# TLE984x register map
Vendor: Infineon Technologies AG; File version: 1.6
CPU: CM0 r0p0, little endian, no MPU, no FPU, 2 interrupt priority bits
Registers are 32-bit, read-write, no defined reset value unless marked. A register's access mark holds for its fields unless they carry their own. Offsets are from the block's base; [hi:lo] are bit positions; {n}, {i} and the like mark numbered series; 'fields as' and 'values as' point back to an identical list.

## SCU
Base 0x50005000
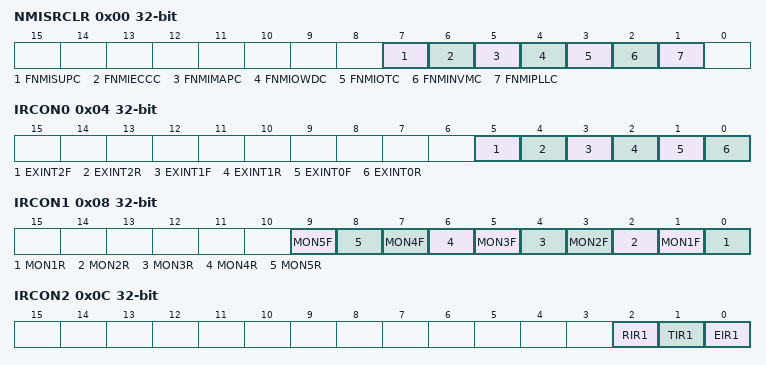
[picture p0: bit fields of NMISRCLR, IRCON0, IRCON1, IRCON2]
0x00 NMISRCLR wo — NMI Status Clear Register
  [all] fields
    0=Interrupt event is not cleared; 1=Interrupt event is cleared
  [7] FNMISUPC — Supply Prewarning NMI Flag
  [6] FNMIECCC — ECC Error NMI Flag
  [5] FNMIMAPC — NVM Map Error NMI Flag
  [4] FNMIOWDC — Oscillator Watchdog NMI Flag
  [3] FNMIOTC — Overtemperature NMI Flag
  [2] FNMINVMC — NVM Operation Complete NMI Flag
  [1] FNMIPLLC — PLL NMI Flag
0x04 IRCON0 ro — Interrupt Request Register 0
  [5] EXINT2F — Interrupt Flag for External Interrupt 2x on falling edge
    0=Interrupt on falling edge event has not occurred; 1=Interrupt on falling edge event has occurred
  [4] EXINT2R — Interrupt Flag for External Interrupt 2x on rising edge
    0=Interrupt on rising edge event has not occurred; 1=Interrupt on rising edge event has occurred
  [3] EXINT1F — Interrupt Flag for External Interrupt 1x on falling edge
    values as EXINT2F
  [2] EXINT1R — Interrupt Flag for External Interrupt 1x on rising edge
    values as EXINT2R
  [1] EXINT0F — Interrupt Flag for External Interrupt 0x on falling edge
    values as EXINT2F
  [0] EXINT0R — Interrupt Flag for External Interrupt 0x on rising edge
    values as EXINT2R
0x08 IRCON1 ro — Interrupt Request Register 1
  [2n-1] MON{n}F (n=1..5) — Interrupt Flag for MON{n}x on falling edge
    values as IRCON0.EXINT2F
  [2n-2] MON{n}R (n=1..5) — Interrupt Flag for MON{n}x on rising edge
    values as IRCON0.EXINT2R
0x0C IRCON2 ro — Interrupt Request Register 2
  [all] fields
    0=Interrupt event has not occurred; 1=Interrupt event has occurred
  [2] RIR1 — Receive Interrupt Flag for SSC1
  [1] TIR1 — Transmit Interrupt Flag for SSC1
  [0] EIR1 — Error Interrupt Flag for SSC1
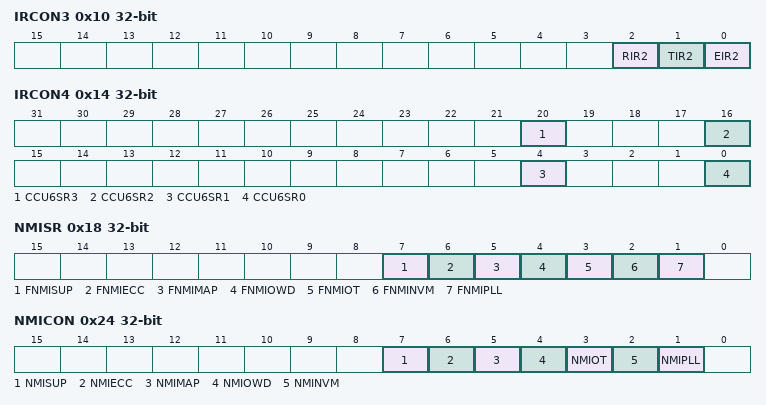
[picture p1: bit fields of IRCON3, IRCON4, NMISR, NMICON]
0x10 IRCON3 ro — Interrupt Request Register 3
  [all] fields
    values as the fields of IRCON2
  [2] RIR2 — Receive Interrupt Flag for SSC2
  [1] TIR2 — Transmit Interrupt Flag for SSC2
  [0] EIR2 — Error Interrupt Flag for SSC2
0x14 IRCON4 ro — Interrupt Request Register 4
  [all] fields
    values as the fields of IRCON2
  [20] CCU6SR3 — Interrupt Flag 3 for CCU6
  [16] CCU6SR2 — Interrupt Flag 2 for CCU6
  [4] CCU6SR1 — Interrupt Flag 1 for CCU6
  [0] CCU6SR0 — Interrupt Flag 0 for CCU6
0x18 NMISR ro — NMI Status Register
  [7] FNMISUP — Supply Prewarning NMI Flag
    0=No supply prewarning NMI has occurred; 1=Supply prewarning has occurred
  [6] FNMIECC — ECC Error NMI Flag
    0=No uncorrectable ECC error has occurred on NVM, XRAM; 1=Uncorrectable ECC error has occurred on NVM, RAM
  [5] FNMIMAP — NVM Map Error NMI Flag
    0=No NVM Map Error NMI has occurred; 1=NVM Map Error has occurred
  [4] FNMIOWD — Oscillator Watchdog NMI Flag
    0=No oscillator watchdog NMI has occurred; 1=Oscillator watchdog event has occurred
  [3] FNMIOT — Overtemperature NMI Flag
    0=No OT NMI has occurred; 1=OT NMI event has occurred
  [2] FNMINVM — NVM Operation Complete NMI Flag
    0=No NVM NMI has occurred; 1=NVM operation complete event has occurred
  [1] FNMIPLL — PLL NMI Flag
    0=No PLL NMI has occurred; 1=PLL loss-of-lock to the external crystal has occurred
0x1C IEN0 — Interrupt Enable Register 0
  [31] EA — Global Interrupt Mask
    0=All pending interrupt requests (except NMI) are blocked from the core; 1=Pending interrupt requests are not blocked from the core
0x20 VTOR — Vector Table Reallocation Register
  [1:0] VTOR_BYP — Vector Table Bypass Mode
    0=VTOR is not remapped (ROM) (Start Address: 0x0000000000); 1=VTOR is remapped to RAM (Start Address: 0x1800000000); 2=VTOR is remapped to NVM (Start Address: 0x1100000000, begin of Customer BSL Region); 3=VTOR is remapped to NVM (Start Address: Begin of NVM Linear region after customer BSL region)
0x24 NMICON — NMI Control Register
  [7] NMISUP — Supply Prewarning NMI Enable
    0=Supply NMI is disabled; 1=Supply NMI is enabled
  [6] NMIECC — ECC Error NMI Enable
    0=ECC Error NMI is disabled; 1=ECC Error NMI is enabled
  [5] NMIMAP — NVM Map Error NMI Enable
    0=NVM Map Error NMI is disabled; 1=NVM Map Error NMI is enabled
  [4] NMIOWD — Oscillator Watchdog NMI Enable
    0=Oscillator watchdog NMI is disabled; 1=Oscillator watchdog NMI is enabled
  [3] NMIOT — NMI OT Enable
    0=NMI OT is disabled; 1=NMI OT is enabled
  [2] NMINVM — NVM Operation Complete NMI Enable
    0=NVM operation complete NMI is disabled; 1=NVM operation complete NMI is enabled
  [1] NMIPLL — PLL Loss of Lock NMI Enable
    0=PLL Loss of Lock NMI is disabled; 1=PLL Loss of Lock NMI is enabled
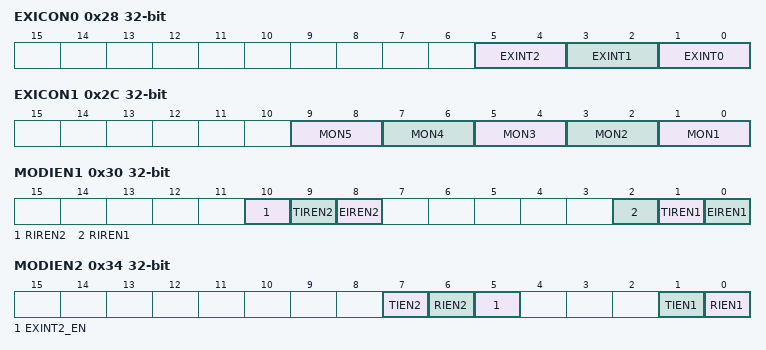
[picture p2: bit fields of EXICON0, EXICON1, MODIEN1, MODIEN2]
0x28 EXICON0 — External Interrupt Control Register 0
  [all] fields
    0=Interrupt disabled; 1=Interrupt on rising edge; 2=Interrupt on falling edge; 3=Interrupt on both rising and falling edge
  [5:4] EXINT2 — External Interrupt 2 Trigger Select
  [3:2] EXINT1 — External Interrupt 1 Trigger Select
  [1:0] EXINT0 — External Interrupt 0 Trigger Select
0x2C EXICON1 — External Interrupt Control Register 1
  [all] fields
    0=external interrupt MON is disabled; 1=Interrupt on rising edge; 2=Interrupt on falling edge; 3=Interrupt on both rising and falling edge
  [2n-1:2n-2] MON{n} (n=1..5) — MON{n} Input Trigger Select
0x30 MODIEN1 — Peripheral Interrupt Enable Register 1
  [10] RIREN2 — SSC 2 Receive Interrupt Enable
    0=Receive interrupt is disabled; 1=Receive interrupt is enabled
  [9] TIREN2 — SSC 2 Transmit Interrupt Enable
    0=Transmit interrupt is disabled; 1=Transmit interrupt is enabled
  [8] EIREN2 — SSC 2 Error Interrupt Enable
    0=Error interrupt is disabled; 1=Error interrupt is enabled
  [2] RIREN1 — SSC 1 Receive Interrupt Enable
    values as RIREN2
  [1] TIREN1 — SSC 1 Transmit Interrupt Enable
    values as TIREN2
  [0] EIREN1 — SSC 1 Error Interrupt Enable
    0=Error interrupt is disabled; 1=Error interrupt is enabled
0x34 MODIEN2 — Peripheral Interrupt Enable Register 2
  [7] TIEN2 — UART 2 Transmit Interrupt Enable
    values as MODIEN1.TIREN2
  [6] RIEN2 — UART 2 Receive Interrupt Enable
    values as MODIEN1.RIREN2
  [5] EXINT2_EN — External Interrupt 2 Enable
    0=External interrupt is disabled; 1=External interrupt is enabled
  [1] TIEN1 — UART 1 Transmit Interrupt Enable
    values as MODIEN1.TIREN2
  [0] RIEN1 — UART 1 Receive Interrupt Enable
    values as MODIEN1.RIREN2
0x38 MODIEN3 — Peripheral Interrupt Enable Register 3
  [0] IE0 — External Interrupt Enable
    0=disabled; 1=enabled
0x3C MODIEN4 — Peripheral Interrupt Enable Register 4
  [0] IE1 — External Interrupt Enable
    0=disabled; 1=enabled
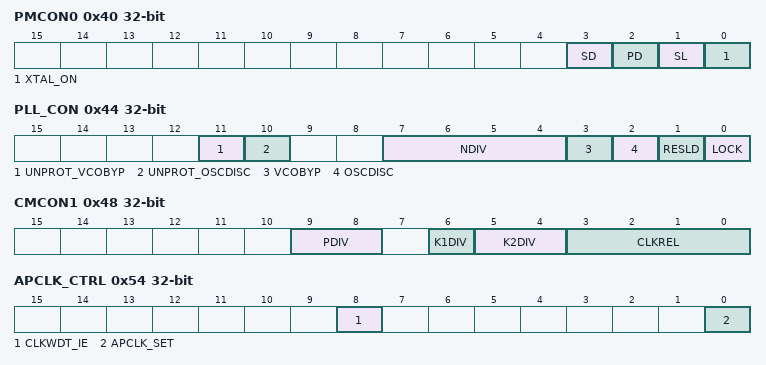
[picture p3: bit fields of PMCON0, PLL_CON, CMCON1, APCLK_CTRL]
0x40 PMCON0 — Power Mode Control Register 0
  [3] SD — Slow Down Mode Enable. Active High.
  [2] PD — Power Down Mode (Stop mode) Enable. Active High.
  [1] SL — Sleep Mode Enable. Active High.
  [0] XTAL_ON — OSC_HP Operation in Power Down Mode
    0=OSC_HP (XTAL) will be put to Power Down mode by hardware in power save mode; 1=OSC_HP (XTAL) continues to operate in Power Down mode, if enabled by SCU_OSC_CON.XPD
0x44 PLL_CON access per field — PLL Control Register
  [11] UNPROT_VCOBYP wo — Unprotect write access of VCO_BYP
  [10] UNPROT_OSCDISC wo — Unprotect write access of OSC_DISC
  [7:4] NDIV rw — PLL N-Divider
    0=N = 48; 1=N = 50; 2=N = 51; 3=N = 52; 4=N = 54; 5=N = 60; 6=N = 67; 7=N = 72; 8=N = 75; 9=N = 78; 10=N = 80; 11=N = 88; 12=N = 90; 13=N = 94; 14=N = 100; 15=N = 160
  [3] VCOBYP rw — PLL VCO Bypass Mode Select
    0=Normal (or freerunning) operation (default); 1=Prescaler Mode; VCO is bypassed (PLL output clock is derived from input clock divided by K1-divider)
  [2] OSCDISC rw — Oscillator Disconnect
    0=Oscillator is connected to the PLL; 1=Oscillator is disconnected to the PLL
  [1] RESLD rw — Restart Lock Detection
    0=No effect; 1=Reset lock flag and restart lock detection
  [0] LOCK ro — PLL Lock Status Flag
    0=The frequency difference of fREF and fDIV is greater than allowed. The VCO part of the PLL can not lock on a target frequency.; 1=The frequency difference of fREF and fDIV is small enough to enable a stable VCO operation
0x48 CMCON1 — Clock Control Register 1
  [9:8] PDIV — PLL PDIV-Divider
  [6] K1DIV — PLL K1-Divider
    0=K1 = 2; 1=K1 = 1
  [5:4] K2DIV — PLL K2-Divider
    {v}=K2 = {v+2} (v=0..3)
  [3:0] CLKREL — Slow Down Clock Divider for fCCLK Generation
    0=fsys; 1=fsys/2; 2=fsys/3; 3=fsys/4; 4=fsys/8; 5=fsys/16; 6=fsys/24; 7=fsys/32; 8=fsys/48; 9=fsys/64; 10=fsys/96; 11=fsys/128; 12=fsys/192; 13=fsys/256; 14=fsys/384; 15=fsys/512
0x4C CMCON2 — Clock Control Register 2
  [0] PBA0CLKREL — PBA0 Clock Divider
    0=divide by 1; 1=divide by 2
0x54 APCLK_CTRL — Analog Peripheral Clock Control Register
  [8] CLKWDT_IE — Clock Watchdog Interrupt Enable
    0=Interrupt disabled; 1=Interrupt enabled
  [0] APCLK_SET — Set and Overtake Flag for Clock Settings
    0=Clock Settings are ignored (previous values are held); 1=Clock Settings are overtaken
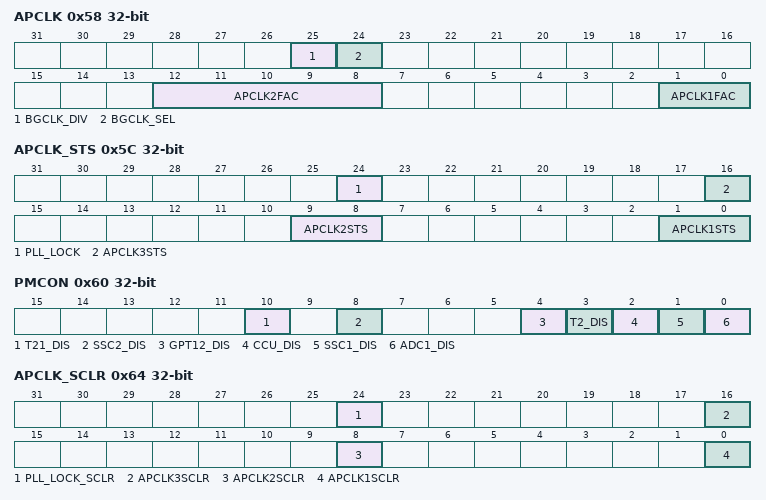
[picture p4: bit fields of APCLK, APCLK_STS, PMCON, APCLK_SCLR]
0x58 APCLK — Analog Peripheral Clock Register
  [25] BGCLK_DIV — Bandgap Clock Divider
    0=divide by 2; 1=divide by 1
  [24] BGCLK_SEL — Bandgap Clock Selection
    0=LP_CLK is selected; 1=fsys is selected
  [12:8] APCLK2FAC — Slow Down Clock Divider for TFILT_CLK Generation
    0=fsys; {v}=fsys/{v+1} (v=1..11); 30=fsys/24; 31=fsys/32
  [1:0] APCLK1FAC — Analog Module Clock Factor
    {v}=Divide by {v+1} (v=0..3)
0x5C APCLK_STS ro — Analog Peripheral Clock Status Register
  [24] PLL_LOCK — PLL LOCK Status
    0=PLL has not locked; 1=PLL has locked
  [16] APCLK3STS — Loss of Clock Status
    0=No loss of clock; 1=Loss of Lock occurred
  [9:8] APCLK2STS — Analog Peripherals Clock Status
    0=The TFILT_CLK clock is in the required range; 1=The TFILT_CLK clock exceeds the higher limit; 2=The TFILT_CLK clock exceeds the lower limit; 3=The TFILT_CLK clock is not inside the specified limit
  [1:0] APCLK1STS — Analog Peripherals Clock Status
    0=The MI_CLK clock is in the required range; 1=The MI_CLK clock exceeds the higher limit; 2=The MI_CLK clock exceeds the lower limit; 3=The MI_CLK clock is not inside the specified limit
0x60 PMCON — Peripheral Management Control Register
  [10] T21_DIS — T21 Disable Request. Active high.
    0=T21 is in normal operation. (default); 1=Request to disable the T21
  [8] SSC2_DIS — SSC2 Disable Request. Active high.
    0=SSC is in normal operation. (default); 1=Request to disable the SSC
  [4] GPT12_DIS — General Purpose Timer 12 Disable Request. Active high.
    0=GPT12 is in normal operation. (default); 1=Request to disable the GPT12
  [3] T2_DIS — T2 Disable Request. Active high.
    0=T2 is in normal operation. (default); 1=Request to disable the T2
  [2] CCU_DIS — CCU Disable Request. Active high.
    0=CCU is in normal operation. (default); 1=Request to disable the CCU
  [1] SSC1_DIS — SSC1 Disable Request. Active high.
    values as SSC2_DIS
  [0] ADC1_DIS — ADC1 Disable Request. Active high.
    0=ADC1 is in normal operation. (default); 1=Request to disable the ADC
0x64 APCLK_SCLR wo — Analog Peripheral Clock Status Clear Register
  [24] PLL_LOCK_SCLR — PLL Lock Status Clear
  [16] APCLK3SCLR — Analog Peripherals Clock 3 Status Clear
  [8] APCLK2SCLR — Analog Peripherals Clock Status Clear
  [0] APCLK1SCLR — Analog Peripherals Clock Status Clear
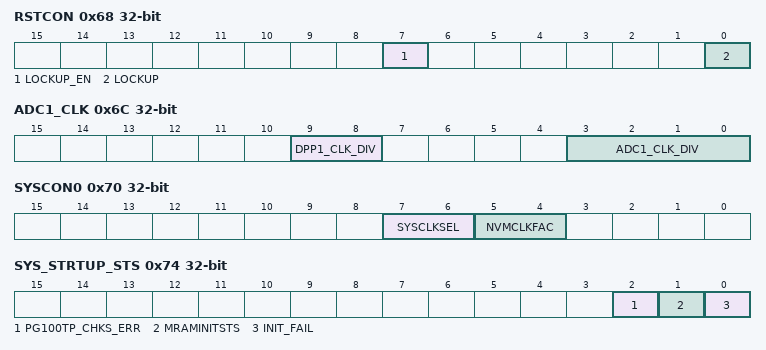
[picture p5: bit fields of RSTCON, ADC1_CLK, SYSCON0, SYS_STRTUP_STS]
0x68 RSTCON — Reset Control Register
  [7] LOCKUP_EN — Lockup Reset Enable Flag
    0=Lockup is disabled; 1=Lockup is enabled
  [0] LOCKUP — Lockup Flag
    0=Lockup Status not active; 1=Lockup Status active
0x6C ADC1_CLK — ADC1 Peripheral Clock Register
  [9:8] DPP1_CLK_DIV — ADC1 Post processing clock divider
    {v}=Divide by {v+1} (v=0..3)
  [3:0] ADC1_CLK_DIV — ADC1 Clock divider
    {v}=Divide by {v+1} (v=0..4); 15=Divide by 16
0x70 SYSCON0 access per field — System Control Register 0
  [7:6] SYSCLKSEL rw — System Clock Select
    0=The PLL clock output signal fPLL is used; 1=The direct clock input from fOSC is used; 2=The direct low-precision clock input from fLP_CLK is used; 3=The direct input from internal oscillator fINTOSC is used
  [5:4] NVMCLKFAC ro — NVM Access Clock Factor
    {v}=Divide by {v+1} (v=0..3)
0x74 SYS_STRTUP_STS ro — System Startup Status Register
  [2] PG100TP_CHKS_ERR — 100 TP Page Checksum Error
  [1] MRAMINITSTS — Map RAM Initialisation Status
  [0] INIT_FAIL — Initialization at startup failed
0x78 WAKECON — Wakeup Interrupt Control Register
  [0] WAKEUPEN — Wakeup Interrupt Enable
    0=wakeup interrupt is disabled; 1=wakeup interrupt is enabled
0x7C IRCON5 ro — Interrupt Request Register 5
  [0] WAKEUP — Interrupt Flag for Wakeup
    values as the fields of IRCON2
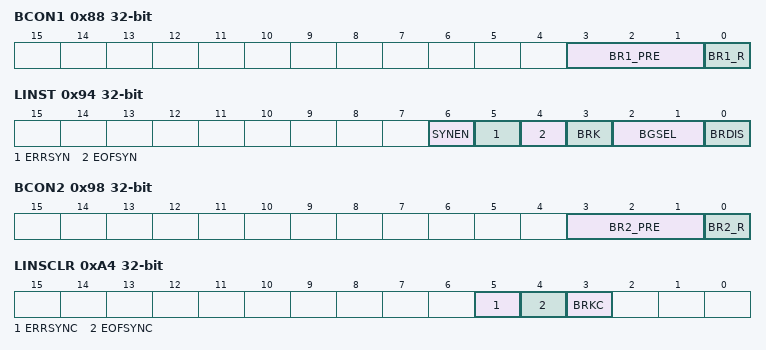
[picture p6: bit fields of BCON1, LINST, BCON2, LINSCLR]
0x88 BCON1 — Baud Rate Control Register 1
  [3:1] BR1_PRE — Prescaler Bit
    0=fDIV = fPCLK; 1=fDIV = fPCLK/2; 2=fDIV = fPCLK/4; 3=fDIV = fPCLK/8; 4=fDIV = fPCLK/16; 5=fDIV = fPCLK/32
  [0] BR1_R — Baud Rate Generator Run Control Bit
    0=Baud-rate generator disabled; 1=Baud-rate generator enabled
0x8C BGL1 — Baud Rate Timer/Reload Register, Low Byte 1
  [4:0] BG1_FD_SEL — Fractional Divider Selection
0x90 BG1 — Baud Rate Timer/Reload Register
  [10:0] BG1_BR_VALUE — Baud Rate Timer/Reload Value UART1
    0=Baud-rate timer is bypassed; 1=1; 2=2; 0x7FE=2046; 0x7FF=2047
0x94 LINST access per field — LIN Status Register
  [6] SYNEN rw — End of SYN Byte and SYN Byte Error Interrupts Enable
    0=End of SYN Byte and SYN Byte Error Interrupts are not enabled; 1=End of SYN Byte and SYN Byte Error Interrupts are enabled
  [5] ERRSYN ro — SYN Byte Error Interrupt Flag
    0=Error is not detected in SYN Byte; 1=Error is detected in SYN Byte
  [4] EOFSYN ro — End of SYN Byte Interrupt Flag
    0=End of SYN Byte is not detected; 1=End of SYN Byte is detected
  [3] BRK ro — Break Field Flag
    0=Break Field is not detected; 1=Break Field is detected
  [2:1] BGSEL rw — Baud Rate Select for Detection
  [0] BRDIS rw — Baud Rate Detection Disable
    0=Break/Synch detection is enabled; 1=Break/Synch detection is disabled
0x98 BCON2 — Baud Rate Control Register 2
  [3:1] BR2_PRE — Prescaler Bit
    values as BCON1.BR1_PRE
  [0] BR2_R — Baud Rate Generator Run Control Bit
    values as BCON1.BR1_R
0x9C BGL2 — Baud Rate Timer/Reload Register, Low Byte 2
  [4:0] BG2_FD_SEL — Fractional Divider Selection
0xA0 BG2 — Baud Rate Timer/Reload Register
  [10:0] BG2_BR_VALUE — Baud Rate Timer/Reload Value UART2
    values as BG1.BG1_BR_VALUE
0xA4 LINSCLR wo — LIN Status Clear Register
  [5] ERRSYNC — SYN Byte Error Interrupt Flag
    0=Error in SYN Byte not cleared; 1=Error in SYN Byte cleared
  [4] EOFSYNC — End of SYN Byte Interrupt Flag Clear
    0=End of SYN Byte is not cleared; 1=End of SYN Byte is cleared
  [3] BRKC — Break Field Flag Clear
    0=Break Field is not cleared; 1=Break Field is cleared
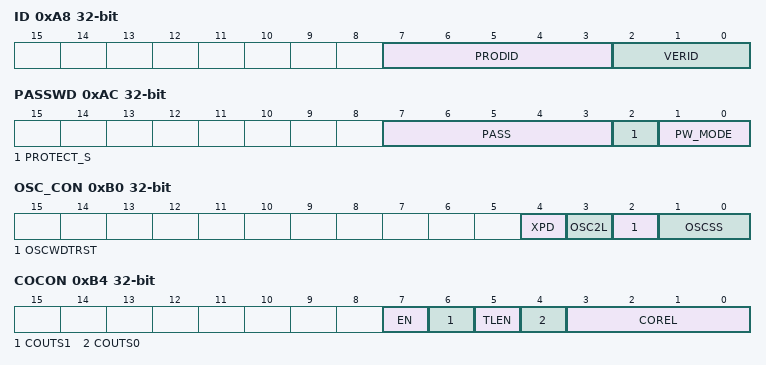
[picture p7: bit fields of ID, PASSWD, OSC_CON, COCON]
0xA8 ID ro — Identity Register
  [7:3] PRODID — Product ID
  [2:0] VERID — Version ID
0xAC PASSWD access per field — Password Register
  [7:3] PASS rw — Password Bits
    24=Enables writing of the bit field MODE; 19=Opens access to writing of all protected bits; 21=Closes access to writing of all protected bits
  [2] PROTECT_S ro — Bit-Protection Signal Status Bit
    0=Software is able to write to all protected bits; 1=Software is unable to write to any protected bits
  [1:0] PW_MODE rw — Bit-Protection Scheme Control Bit
    0=Scheme Disabled; 3=Scheme Enabled (default)
0xB0 OSC_CON access per field — OSC Control Register
  [4] XPD rw — XTAL (OSC_HP) Power Down Control
    0=XTAL (OSC_HP) is not powered down; 1=XTAL (OSC_HP) is powered down
  [3] OSC2L ro — OSC-Too-Low Condition Flag
    0=fOSC is above threshold; 1=fOSC is below threshold
  [2] OSCWDTRST rw — Oscillator Watchdog Reset
    0=No effect; 1=Reset OSC2L flag and restart the oscillator watchdog of the PLL
  [1:0] OSCSS rw — Oscillator Source Select
    0=PLL internal oscillator OSC_PLL (fINT) is selected synchronously as fR; 1=XTAL (fOSC from OSC_HP) is selected synchronously as fR; 0b1x=PLL internal oscillator OSC_PLL (fINT) is selected asynchronously as fR
0xB4 COCON — Clock Output Control Register
  [7] EN — CLKOUT Enable
    0=No external clock signal is provided; 1=The configured external clock signal is provided
  [6] COUTS1 — Clock Out Source Select Bit 1
    0=fCCLK is selected; 1=Based on setting of COUTS0
  [5] TLEN — Toggle Latch Enable
    0=Toggle Latch is disabled. Clock output frequency is chosen by the bit field COREL.; 1=Toggle Latch is enabled. Clock output frequency is half of the frequency that is chosen by the bit field COREL. The resulting output frequency has 50% duty cycle.
  [4] COUTS0 — Clock Out Source Select Bit 0
    0=Oscillator output frequency is selected; 1=Clock output frequency is chosen by the bit field COREL
  [3:0] COREL — Clock Output Divider
    0=fsys; 1=fsys/2; 2=fsys/3; 3=fsys/4; 4=fsys/6; 5=fsys/8; 6=fsys/10; 7=fsys/12; 8=fsys/14; 9=fsys/16; 10=fsys/18; 11=fsys/20; 12=fsys/24; 13=fsys/32; 14=fsys/36; 15=fsys/40
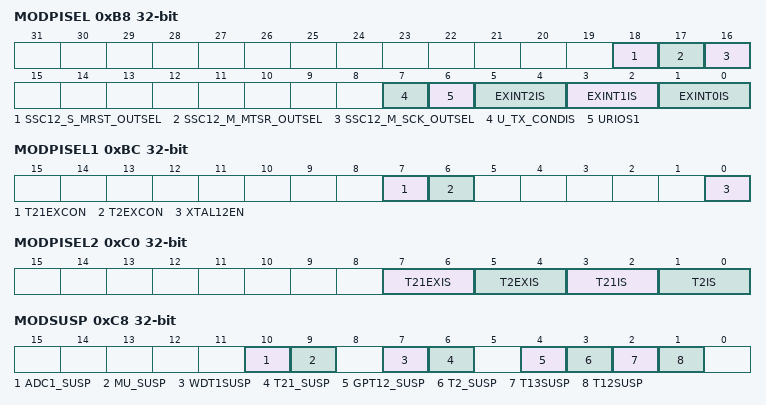
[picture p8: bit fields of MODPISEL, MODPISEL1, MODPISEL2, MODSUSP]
0xB8 MODPISEL — Peripheral Input Select Register
  [18] SSC12_S_MRST_OUTSEL — Output selection for SSC12_S_MRST
    0=SSC1_S_MRST; 1=SSC2_S_MRST
  [17] SSC12_M_MTSR_OUTSEL — Output selection for SSC12_M_MTSR
    0=SSC1_M_MTSR; 1=SSC2_M_MTSR
  [16] SSC12_M_SCK_OUTSEL — Output selection for SSC12_M_SCK
    0=SSC1_M_SCK; 1=SSC2_M_SCK
  [7] U_TX_CONDIS — UART1 TxD Connection Disable
    0=UART1-TX-Output -LIN Transmitter TX Input Connection available; 1=UART1-TX-Output -LIN Transmitter TX Input Connection not available (can be stimulated by external port pin)
  [6] URIOS1 — UART1 Input/Output Select
    0=UART1 Receiver Input RXD1_0 (Connection to LIN is available); 1=UART1 Receiver Input RXD1_1 (Connection to LIN is not available)
  [5:4] EXINT2IS — External Interrupt 2 Input Select
    {v}=External Interrupt Input EXINT2_{v} is selected (v=0..3)
  [3:2] EXINT1IS — External Interrupt 1 Input Select
    {v}=External Interrupt Input EXINT1_{v} is selected (v=0..3)
  [1:0] EXINT0IS — External Interrupt 0 Input Select
    {v}=External Interrupt Input EXINT0_{v} is selected (v=0..3)
0xBC MODPISEL1 — Peripheral Input Select Register 1
  [7] T21EXCON — Timer 21 External Input Control
    0=Timer 21 Input T21EX is selected by bit field SCU_MODPISEL2.T21EXIS; 1=Timer 21 Input T21EX is connected to signal from CCU6 (Output >cc6_ch0)
  [6] T2EXCON — Timer 2 External Input Control
    0=Timer 2 Input T2EX is selected by bit field SCU_MODPISEL2.T2EXIS; 1=Timer 2 Input T2EX is connected to signal from CCU6 (Output >cc6_cout60)
  [0] XTAL12EN — Pins XTAL1/2 Enable Bit
    0=Pins XTAL1/2 is not available. This setting overrides the OSC_CON.XPD setting.; 1=Pins XTAL1/2 is available
0xC0 MODPISEL2 — Peripheral Input Select Register 2
  [7:6] T21EXIS — Timer 21 External Input Select
    {v}=Timer 21 Input T21EX_{v} is selected (v=0..3)
  [5:4] T2EXIS — Timer 2 External Input Select
    {v}=Timer 2 Input T2EX_{v} is selected (v=0..3)
  [3:2] T21IS — Timer 21 Input Select
    0=Timer 21 Input T21_0 is selected; 1=Timer 21 Input T21_1 is selected; 2=Timer 21 Input T21_2 is selected
  [1:0] T2IS — Timer 2 Input Select
    0=Timer 2 Input T2_0 is selected; 1=Timer 2 Input T2_1 is selected; 2=Timer 2 Input T2_2 is selected
0xC4 MODPISEL3 — Peripheral Input Select Register 3
  [6] URIOS2 — UART2 Input/Output Select
    0=UART2 Receiver Input RXD2 is selected; 1=UART2 Receiver Input RXD2 is selected (same as 0-setting)
0xC8 MODSUSP — Module Suspend Control Register
  [10] ADC1_SUSP — ADC1 Unit Debug Suspend Bit
    0=ADC1 will not be suspended; 1=ADC1 will be suspended
  [9] MU_SUSP — Measurement Unit Debug Suspend Bit
    0=MU will not be suspended; 1=MU will be suspended
  [7] WDT1SUSP — Watchdog Timer 1 Debug Suspend Bit
    0=WDT1 will not be suspended; 1=WDT1 will be suspended
  [6] T21_SUSP — Timer21 Debug Suspend Bit
    0=Timer21 will not be suspended; 1=Timer21 will be suspended
  [4] GPT12_SUSP — GPT12 Debug Suspend Bit
    0=GPT12 will not be suspended; 1=GPT12 will be suspended
  [3] T2_SUSP — Timer2 Debug Suspend Bit
    0=Timer2 will not be suspended; 1=Timer2 will be suspended
  [2] T13SUSP — Timer 13 Debug Suspend Bit
    0=Timer 13 in Capture/Compare Unit will not be suspended; 1=Timer 13 in Capture/Compare Unit will be suspended
  [1] T12SUSP — Timer 12 Debug Suspend Bit
    0=Timer 12 in Capture/Compare Unit will not be suspended; 1=Timer 12 in Capture/Compare Unit will be suspended
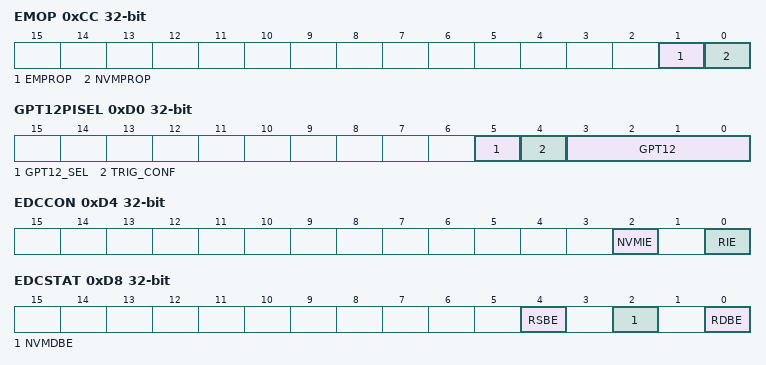
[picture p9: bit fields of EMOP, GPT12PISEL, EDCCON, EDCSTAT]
0xCC EMOP — Emergency and Program Operation Status Register
  [1] EMPROP — Emergency Program Operation Status Bit
    0=No emergency program operation is started; 1=Emergency program operation is started
  [0] NVMPROP — NVM Program Operation Status Bit
    0=No NVM program operation is started; 1=NVM program operation is started
0xD0 GPT12PISEL — GPT12 Peripheral Input Select Register
  [5] GPT12_SEL — CCU6 Trigger Configuration.
    0=CCU6_INT is triggered by Timer21; 1=CCU6_INT is triggered by GPT12PISEL.GPT12
  [4] TRIG_CONF — CCU6 Trigger Configuration.
    0=Trigger is just for one measurement (default); 1=Trigger is present until next input edge (selected by GPT12) - continuous measurement
  [3:0] GPT12 — GPT12 TIN3B / TIN4D Input Select
    0=CC60; 1=CC61; 2=CC62; 3=T12 ZM; 4=T12 PM; 5=T12 CM0; 6=T12 CM1; 7=T12 CM2; 8=T13 PM; 9=T13 ZM; 10=T13 CM; 11=any pos or neg edge on CC60/61/62
0xD4 EDCCON — Error Detection and Correction Control Register
  [2] NVMIE — NVM Double Bit ECC Error Interrupt Enable
    0=No NMI is generated when a double bit ECC error occurs reading NVM; 1=An NMI is generated when a double bit ECC error occurs reading NVM
  [0] RIE — RAM Double Bit ECC Error Interrupt Enable
    0=No NMI is generated when a double bit ECC error occurs reading RAM; 1=An NMI is generated when a double bit ECC error occurs reading RAM
0xD8 EDCSTAT ro — Error Detection and Correction Status Register
  [4] RSBE — RAM Single Bit Error
    0=No single bit error on RAM has occurred; 1=A single bit error on RAM has occurred
  [2] NVMDBE — NVM Double Bit Error
    0=No double bit error on NVM has occurred; 1=A double bit error on NVM has occurred
  [0] RDBE — RAM Double Bit Error
    0=No double bit error on RAM has occurred; 1=A double bit error on RAM has occurred
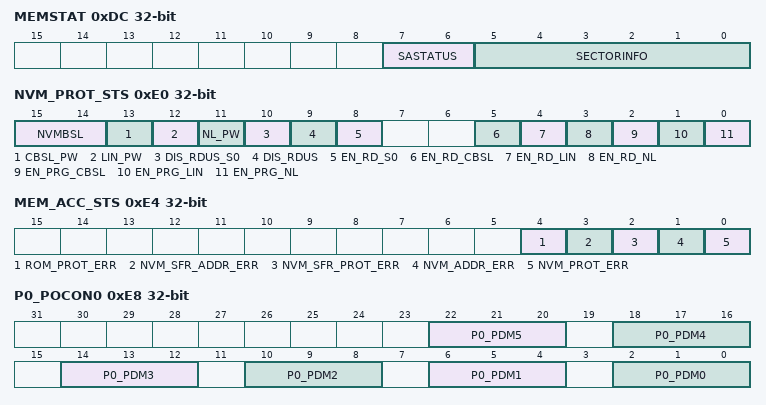
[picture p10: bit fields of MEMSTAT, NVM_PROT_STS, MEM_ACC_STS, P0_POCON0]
0xDC MEMSTAT — Memory Status Register
  [7:6] SASTATUS — Service Algorithm Status
    0=Depending on SECTORINFO, there are two possible outcomes: For SECTORINFO = 00H, NVM initialization is successful and no SA is executed. For SECTORINFO = values other than 00H, SA execution is successful and only one map error is fixed.; 1=SA execution is successful. More than one mapping error is fixed.; 0b1x=SA execution is not successful. Map error exists in the mapped sector.
  [5:0] SECTORINFO — Sector Information
0xE0 NVM_PROT_STS ro — NVM Protection Status Register
  [15:14] NVMBSL — CBSL Region Size Definition
    0=CBSL Size is 4K; 1=CBSL Size is 8K; 2=CBSL Size is 12K; 3=CBSL Size is 16K
  [13] CBSL_PW — Status of CBSL Region Password / Protection
    0=CBSL Region Password is not installed; CBSL region is not protected; 1=CBSL Region Password is installed; CBSL region is protected
  [12] LIN_PW — Status of Linear Region Password / Protection
    0=Linear Region Password is not installed; Linear region is not protected; 1=Linear Region Password is installed; Linear region is protected
  [11] NL_PW — Status of Non-Linear Region Password / Protection
    0=Non-Linear Region Password is not installed; Linear region is not protected; 1=Non-Linear Region Password is installed; Linear region is protected
  [10] DIS_RDUS_S0 — Configuration of NVM Read Protection for Sector 0 with EN_RD_S0 = 0
    0=only active when nvm_read_S0_unsafe_i = 1 and not for nvm_read_S0_unsafe_i = 0; 1=independent from nvm_read_S0_unsafe_i; Also write accesess to Sector 0 are prevented
  [9] DIS_RDUS — Configuration of NVM Read Protection for Sector 1...n with EN_RD_* = 0
    0=only active when nvm_read_unsafe_i = 1 and not for nvm_read_unsafe_i = 0; 1=independent from nvm_read_unsafe_i; Also write accesess to Sector 1...n are prevented
  [8] EN_RD_S0 — NVM Read Protection for Sector 0
    0=The data in sector 0 can not be read over AHB-Lite Interface; 1=The data in sector 0 can be read over AHB-Lite Interface
  [5] EN_RD_CBSL — NVM Read Protection of Data in CBSL Region
    0=The data in region defined by NVMBSL can not be read; 1=The data in region defined by NVMBSL sectors of can be read
  [4] EN_RD_LIN — NVM Read Protection of Data in Linear Sectors
    0=The data in sectors of the linearly mapped area can not be read; 1=The data in sectors of the linearly mapped area can be read
  [3] EN_RD_NL — NVM Read Protection of Data in Non-Linear Sectors
    0=The data in sectors of the non-linearly mapped area can not be read; 1=The data in sectors of the non-linearly mapped area can be read
  [2] EN_PRG_CBSL — NVM Protection of Data in CBSL Region
    0=The data in region defined by NVMBSL can not be changed; 1=The data in region defined by NVMBSL can be changed (erased or written)
  [1] EN_PRG_LIN — NVM Protection of Data in Linear Sectors
    0=The data in sectors of the linearly mapped area can not be changed; 1=The data in sectors of the linearly mapped area can be changed (erased or written)
  [0] EN_PRG_NL — NVM Protection of Data in Non-Linear Sectors
    0=The data in sectors of the non-linearly mapped area can not be changed; 1=The data in sectors of the non-linearly mapped area can be changed (erased or written)
0xE4 MEM_ACC_STS ro — Memory Access Status Register
  [all] fields
    0=No Protection error; 1=Protection error
  [4] ROM_PROT_ERR — ROM Access Protection
  [3] NVM_SFR_ADDR_ERR — NVM SFR Address Protection
  [2] NVM_SFR_PROT_ERR — NVM SFR Access Protection
  [1] NVM_ADDR_ERR — NVM Address Protection
  [0] NVM_PROT_ERR — NVM Access Protection
0xE8 P0_POCON0 — Port Output Control Register
  [22:20] P0_PDM5 — P0.5 Port Driver Mode
    0=Strong driver and sharp edge mode; 1=Strong driver and medium edge mode; 2=Strong driver and soft edge mode; 3=Weak driver; 4=Medium driver; 5=Medium driver; 6=Medium driver; 7=Weak driver
  [18:16] P0_PDM4 — P0.4 Port Driver Mode
    values as P0_PDM5
  [14:12] P0_PDM3 — P0.3 Port Driver Mode
    values as P0_PDM5
  [10:8] P0_PDM2 — P0.2 Port Driver Mode
    values as P0_PDM5
  [6:4] P0_PDM1 — P0.1 Port Driver Mode
    0=Medium driver; 3=Weak driver; 4=Medium driver; 5=Medium driver; 6=Medium driver; 7=Weak driver
  [2:0] P0_PDM0 — P0.0 Port Driver Mode
    values as P0_PDM1
0xF4 TCCR — Temperature Compensation Control Register
  [1:0] TCC — Temperature Compensation Control
    0=TJ: -40 °C to 0 °C; 1=TJ: 0 °C to 40 °C; 2=TJ: 40 °C to 80 °C; 3=TJ: 80 °C to 150 °C
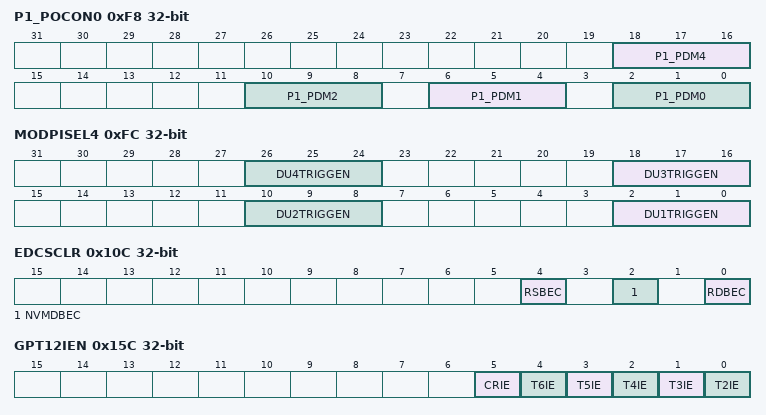
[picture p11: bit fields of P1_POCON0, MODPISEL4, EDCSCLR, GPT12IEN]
0xF8 P1_POCON0 — Port Output Control Register
  [18:16] P1_PDM4 — P1.4 Port Driver Mode
    values as P0_POCON0.P0_PDM5
  [10:8] P1_PDM2 — P1.2 Port Driver Mode
    values as P0_POCON0.P0_PDM1
  [6:4] P1_PDM1 — P1.1 Port Driver Mode
    values as P0_POCON0.P0_PDM1
  [2:0] P1_PDM0 — P1.0 Port Driver Mode
    values as P0_POCON0.P0_PDM1
0xFC MODPISEL4 — Peripheral Input Select Register 4
  [all] fields
    0=CC60 is selected; 1=CC61 is selected; 2=CC62 is selected; 3=COUT60 is selected; 4=COUT61 is selected; 5=COUT62 is selected; 6=T3OUT is selected; 7=COUT63 is selected
  [8n-6:8n-8] DU{n}TRIGGEN (n=1..4) — Differential Unit Trigger Enable
0x10C EDCSCLR wo — Error Detection and Correction Status Clear Register
  [4] RSBEC — RAM Single Bit Error Clear
    0=A single bit error on RAM is not cleared; 1=A single bit error on RAM is cleared
  [2] NVMDBEC — NVM Double Bit Error Clear
    0=A double bit error on NVM is not cleared; 1=A double bit error on NVM is cleared
  [0] RDBEC — RAM Double Bit Error Clear
    0=A double bit error on RAM is not cleared; 1=A double bit error on RAM is cleared
0x15C GPT12IEN — General Purpose Timer 12 Interrupt Enable Register
  [all] fields
    0=Interrupt is disabled; 1=Interrupt is enabled
  [5] CRIE — GPT12 Capture and Reload Interrupt Enable
  [n-2] T{n}IE (n=2..6) — GPT12 T{n} Interrupt Enable
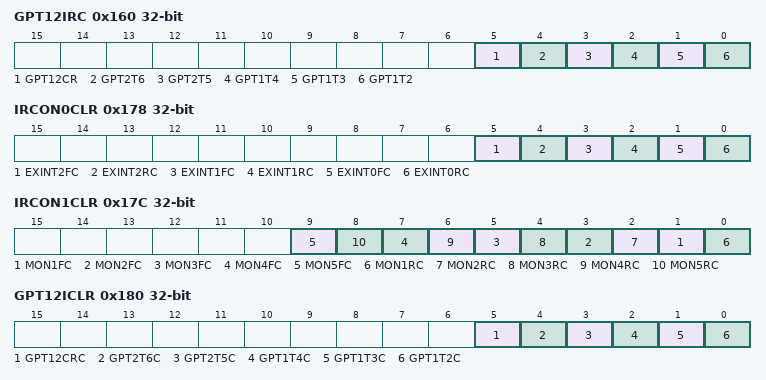
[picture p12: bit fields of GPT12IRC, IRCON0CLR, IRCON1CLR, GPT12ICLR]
0x160 GPT12IRC ro — Timer and Counter Control/Status Register
  [5] GPT12CR — GPT 12 Capture Reload Interrupt Status
    0=No Capture Reload Interrupt has occurred; 1=Capture Reload Interrupt has occurred
  [4] GPT2T6 — GPT Module 2Timer6 Interrupt Status
    0=No Timer 6 Interrupt has occurred; 1=Timer 6 Interrupt has occurred
  [3] GPT2T5 — GPT Module 2 Timer5 Interrupt Status
    0=No Timer 5 Interrupt has occurred; 1=Timer 5 Interrupt has occurred
  [2] GPT1T4 — GPT Module 1 Timer4 Interrupt Status
    0=No Timer 4 Interrupt has occurred; 1=Timer 4 Interrupt has occurred
  [1] GPT1T3 — GPT Module 1 Timer3 Interrupt Status
    0=No Timer 3 Interrupt has occurred; 1=Timer 3 Interrupt has occurred
  [0] GPT1T2 — GPT Module 1 Timer 2 Interrupt Status
    0=No Timer 2 Interrupt has occurred; 1=Timer 2 Interrupt has occurred
0x178 IRCON0CLR wo — Interrupt Request 0 Clear Register
  [all] fields
    values as the fields of NMISRCLR
  [5] EXINT2FC — Interrupt Flag for External Interrupt 2x on falling edge
  [4] EXINT2RC — Interrupt Flag for External Interrupt 2x on rising edge
  [3] EXINT1FC — Interrupt Flag for External Interrupt 1x on falling edge
  [2] EXINT1RC — Interrupt Flag for External Interrupt 1x on rising edge
  [1] EXINT0FC — Interrupt Flag for External Interrupt 0x on falling edge
  [0] EXINT0RC — Interrupt Flag for External Interrupt 0x on rising edge
0x17C IRCON1CLR wo — Interrupt Request 1 Clear Register
  [all] fields
    values as the fields of NMISRCLR
  [2n-1] MON{n}FC (n=1..5) — Interrupt Flag for MON{n}x on falling edge
  [2n-2] MON{n}RC (n=1..5) — Interrupt Flag for MON{n}x on rising edge
0x180 GPT12ICLR wo — Timer and Counter Control/Status Clear Register
  [all] fields
    values as the fields of NMISRCLR
  [5] GPT12CRC — GPT Module 1 Capture Reload Interrupt Status
  [4] GPT2T6C — GPT Module 2 Timer6 Interrupt Status
  [3] GPT2T5C — GPT Module 2 Timer5 Interrupt Status
  [2] GPT1T4C — GPT Module 1 Timer4 Interrupt Status
  [1] GPT1T3C — GPT Module 1 Timer3 Interrupt Status
  [0] GPT1T2C — GPT Module 1 Timer 2 Interrupt Status
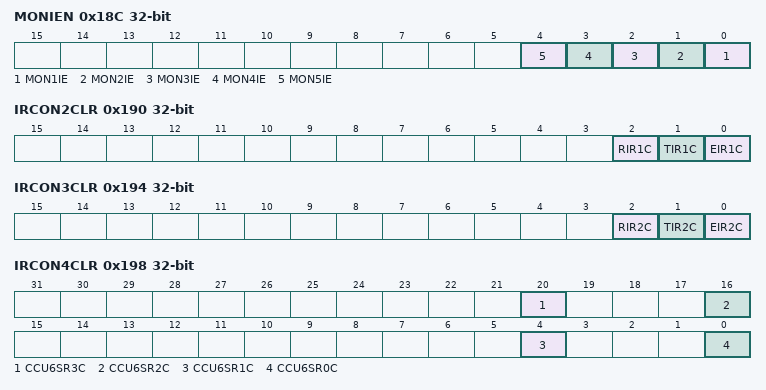
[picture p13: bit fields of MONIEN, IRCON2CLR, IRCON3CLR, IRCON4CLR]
0x18C MONIEN — Monitoring Input Interrupt Enable Register
  [all] fields
    0=disabled; 1=enabled
  [n-1] MON{n}IE (n=1..5) — MON{n} Interrupt Enable
0x190 IRCON2CLR wo — Interrupt Request 2 Clear Register
  [all] fields
    values as the fields of NMISRCLR
  [2] RIR1C — Receive Interrupt Flag for SSC1
  [1] TIR1C — Transmit Interrupt Flag for SSC1
  [0] EIR1C — Error Interrupt Flag for SSC1
0x194 IRCON3CLR wo — Interrupt Request 3 Clear Register
  [all] fields
    values as the fields of NMISRCLR
  [2] RIR2C — Receive Interrupt Flag for SSC2
  [1] TIR2C — Transmit Interrupt Flag for SSC2
  [0] EIR2C — Error Interrupt Flag for SSC2
0x198 IRCON4CLR wo — Interrupt Request 4 Clear Register
  [all] fields
    values as the fields of NMISRCLR
  [20] CCU6SR3C — Interrupt Flag 3 for CCU6
  [16] CCU6SR2C — Interrupt Flag 2 for CCU6
  [4] CCU6SR1C — Interrupt Flag 1 for CCU6
  [0] CCU6SR0C — Interrupt Flag 0 for CCU6
0x19C IRCON5CLR wo — Interrupt Request 5 Clear Register
  [0] WAKEUPC — Clear Flag for Wakeup Interrupt
    values as the fields of NMISRCLR
